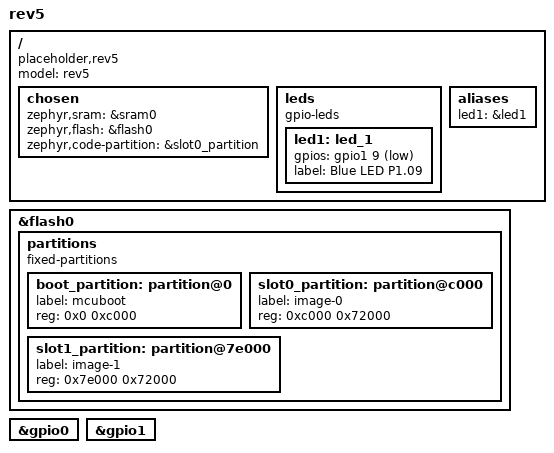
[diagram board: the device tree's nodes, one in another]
// Copyright (c) 2024 Nordic Semiconductor ASA
// SPDX-License-Identifier: Apache-2.0

/dts-v1/;
#include <nordic/nrf52840_qfaa.dtsi>

/ {
    model = "rev5";
    compatible = "placeholder,rev5";

    chosen {
    	zephyr,sram = &sram0;
    	zephyr,flash = &flash0;
    	zephyr,code-partition = &slot0_partition;
    };
    leds {
        compatible = "gpio-leds";
        led1: led_1 {
            gpios = <&gpio1 9 (GPIO_ACTIVE_LOW)>;
            label = "Blue LED P1.09";
        };
    };

    aliases {
        led1 = &led1;
    };
};

&flash0 {
	partitions {
		compatible = "fixed-partitions";
		#address-cells = <1>;
		#size-cells = <1>;

		boot_partition: partition@0 {
			label = "mcuboot";
			reg = <0x0 0xc000>;
		};
		slot0_partition: partition@c000 {
			label = "image-0";
			reg = <0xc000 0x72000>;
		};
		slot1_partition: partition@7e000 {
			label = "image-1";
			reg = <0x7e000 0x72000>;
		};
		// scratch_partition: partition@f0000 {
		// 	label = "image-scratch";
		// 	reg = <0xf0000 0xa000>;
		// };
		// storage_partition: partition@fa000 {
		// 	label = "storage";
		// 	reg = <0xfa000 0x6000>;
		// };
	};
};

&gpio0 {
    status = "okay";
};
&gpio1 {
    status = "okay";
};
